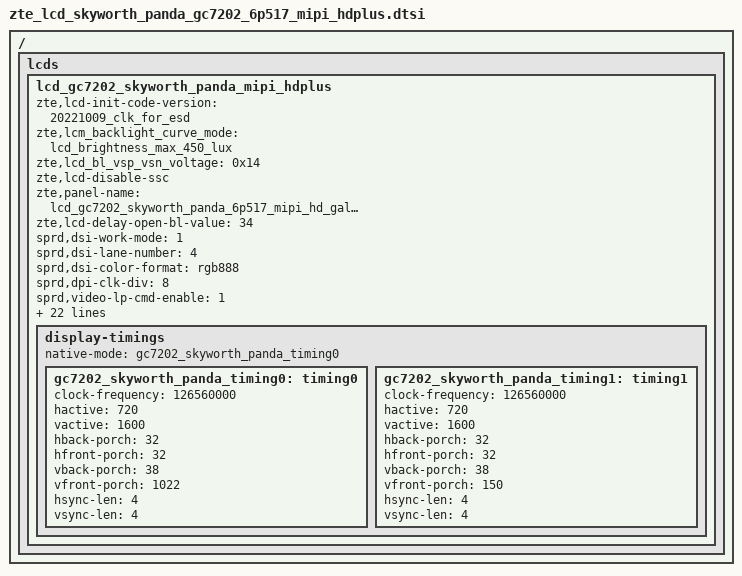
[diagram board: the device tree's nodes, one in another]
/ {
	fragment {
		target-path = "/";
		__overlay__ {
			lcds {
				lcd_gc7202_skyworth_panda_mipi_hdplus: lcd_gc7202_skyworth_panda_mipi_hdplus {
					zte,lcd-init-code-version = "20221009_clk_for_esd";

					zte,lcm_backlight_curve_mode = "lcd_brightness_max_450_lux";
					zte,lcd_bl_vsp_vsn_voltage = <0x14>;
					zte,lcd-disable-ssc;
					zte,panel-name = "lcd_gc7202_skyworth_panda_6p517_mipi_hd_galaxycore_4lane";
					zte,lcd-delay-open-bl-value = <34>;

					sprd,dsi-work-mode = <1>;
					sprd,dsi-lane-number = <4>;
					sprd,dsi-color-format = "rgb888";

					sprd,dpi-clk-div = <8>;
					sprd,video-lp-cmd-enable = <1>;
					sprd,hporch-lp-disable = <1>;

					sprd,phy-bit-clock = <1012480>;
					sprd,phy-escape-clock = <20000>;/* kHz */

					sprd,width-mm = <67932>;
					sprd,height-mm = <150960>;

					sprd,esd-check-enable = <1>;/* 0:close , 1:open */
					sprd,esd-check-mode = <0>;/* 0:REG ,1:TE  */
					sprd,esd-check-period = <2000>;
					sprd,esd-check-register = <0x0A>;
					sprd,esd-check-value = <0x9C>;

		sprd,reset-on-sequence = <1 10>, <0 10>, <1 35>, <0 10>, <1 10>, <0 10>, <1 10>, <0 10>, <1 30>;
		sprd,reset-off-sequence = <1 10>;
		sprd,use-dcs-write;
		sprd,initial-command = [
39 00 00 04 FF 55 AA 66
15 00 00 02 FF 20
15 00 00 02 FB 00
15 00 00 02 FF 21
15 00 00 02 FB 00
15 00 00 02 FF 22
15 00 00 02 FB 00
15 00 00 02 FF 23
15 00 00 02 FB 00
15 00 00 02 FF 24
15 00 00 02 FB 00
15 00 00 02 FF 26
15 00 00 02 FB 00
15 00 00 02 FF 27
15 00 00 02 FB 00
15 00 00 02 FF A3
15 00 00 02 FB 00
15 00 00 02 FF B3
15 00 00 02 FB 00
15 00 00 02 FF C3
15 00 00 02 FB 00
15 00 00 02 FF 22
15 00 00 02 E4 00
15 00 00 02 01 06
15 00 00 02 02 40
15 00 00 02 25 08
15 00 00 02 26 00
15 00 00 02 2E AA
15 00 00 02 2F 00
15 00 00 02 36 09
15 00 00 02 37 00
15 00 00 02 3F AA
15 00 00 02 40 00
15 00 00 02 0E 33
15 00 00 02 DC 00
15 00 00 02 E0 01
15 00 00 02 08 40
15 00 00 02 FF 21
15 00 00 02 01 25
15 00 00 02 02 05
15 00 00 02 03 06
15 00 00 02 04 25
15 00 00 02 05 25
15 00 00 02 06 01
15 00 00 02 07 0F
15 00 00 02 08 0D
15 00 00 02 09 0B
15 00 00 02 0A 09
15 00 00 02 0B 23
15 00 00 02 0C 23
15 00 00 02 0D 25
15 00 00 02 0E 25
15 00 00 02 0F 25
15 00 00 02 10 25
15 00 00 02 11 25
15 00 00 02 12 25
15 00 00 02 13 25
15 00 00 02 14 25
15 00 00 02 15 25
15 00 00 02 16 25
15 00 00 02 17 25
15 00 00 02 18 04
15 00 00 02 19 06
15 00 00 02 1A 25
15 00 00 02 1B 25
15 00 00 02 1C 00
15 00 00 02 1D 0E
15 00 00 02 1E 0C
15 00 00 02 1F 0A
15 00 00 02 20 08
15 00 00 02 21 23
15 00 00 02 22 23
15 00 00 02 23 25
15 00 00 02 24 25
15 00 00 02 25 25
15 00 00 02 26 25
15 00 00 02 27 25
15 00 00 02 28 25
15 00 00 02 29 25
15 00 00 02 2A 25
15 00 00 02 2B 25
15 00 00 02 2D 25
15 00 00 02 45 73
15 00 00 02 7E 03
15 00 00 02 C2 85
15 00 00 02 7F 22
15 00 00 02 8B 22
15 00 00 02 80 02
15 00 00 02 8C 19
15 00 00 02 81 19
15 00 00 02 8D 02
15 00 00 02 AF 40
15 00 00 02 B0 40
15 00 00 02 83 03
15 00 00 02 8F 03
15 00 00 02 84 55
15 00 00 02 90 55
15 00 00 02 85 42
15 00 00 02 91 42
15 00 00 02 87 00
15 00 00 02 93 00
15 00 00 02 2E 00
15 00 00 02 88 A7
15 00 00 02 89 20
15 00 00 02 8A 33
15 00 00 02 94 A7
15 00 00 02 95 20
15 00 00 02 96 33
15 00 00 02 46 54
15 00 00 02 4C 54
15 00 00 02 5E 42
15 00 00 02 64 42
15 00 00 02 82 50
15 00 00 02 8E 50
15 00 00 02 47 02
15 00 00 02 4D 01
15 00 00 02 48 01
15 00 00 02 4E 02
15 00 00 02 5F 06
15 00 00 02 65 07
15 00 00 02 60 07
15 00 00 02 66 06
15 00 00 02 76 40
15 00 00 02 77 40
15 00 00 02 7A 44
15 00 00 02 7B 44
15 00 00 02 6A 42
15 00 00 02 7C 54
15 00 00 02 6B 06
15 00 00 02 6C 07
15 00 00 02 6D 55
15 00 00 02 6E 55
15 00 00 02 49 55
15 00 00 02 4A 55
15 00 00 02 4F 55
15 00 00 02 50 55
15 00 00 02 61 55
15 00 00 02 62 55
15 00 00 02 67 55
15 00 00 02 68 55
15 00 00 02 C6 56
15 00 00 02 D1 13
15 00 00 02 FF B3
15 00 00 02 4A 00
15 00 00 02 7D 28
15 00 00 02 5B 00
15 00 00 02 48 23
15 00 00 02 7C 88
15 00 00 02 3E 03
15 00 00 02 3F 3f
15 00 00 02 5E 10
15 00 00 02 58 84
15 00 00 02 51 51
15 00 00 02 FF 20
15 00 00 02 29 01
15 00 00 02 2D 1F
15 00 00 02 02 21
15 00 00 02 03 21
15 00 00 02 04 46
15 00 00 02 05 46
15 00 00 02 0A 19
15 00 00 02 0B 19
15 00 00 02 0C 43
15 00 00 02 0D 43
15 00 00 02 77 74
15 00 00 02 78 74
15 00 00 02 A5 00
15 00 00 02 A6 FF
15 00 00 02 A9 00
15 00 00 02 AA FF
15 00 00 02 AD 00
15 00 00 02 AE FF
15 00 00 02 B1 00
15 00 00 02 B2 FF
15 00 00 02 C3 00
15 00 00 02 C4 65
15 00 00 02 C5 00
15 00 00 02 C6 65
15 00 00 02 B3 00
15 00 00 02 B4 28
15 00 00 02 B5 01
15 00 00 02 B6 04
15 00 00 02 7E 01
15 00 00 02 7F 00
15 00 00 02 80 01
15 00 00 02 81 00
15 00 00 02 82 00
15 00 00 02 83 04
15 00 00 02 84 04
15 00 00 02 85 01
15 00 00 02 86 A6
15 00 00 02 87 01
15 00 00 02 88 8B
15 00 00 02 8A 03
15 00 00 02 8B 03
15 00 00 02 18 44
15 00 00 02 17 51
15 00 00 02 12 A2
15 00 00 02 15 4C
15 00 00 02 A3 44
15 00 00 02 A7 44
15 00 00 02 D3 06
15 00 00 02 24 99
15 00 00 02 25 16
15 00 00 02 FF 23
39 00 00 11 01 00 00 00 2E 00 5D 00 7D 00 95 00 AA 00 C0 00 CF
39 00 00 11 02 00 DF 01 0D 01 30 01 61 01 82 01 B4 01 DE 01 DF
39 00 00 11 03 02 0B 02 43 02 6B 02 A0 02 C4 02 F6 03 06 03 18
39 00 00 0D 04 03 2C 03 44 03 5E 03 85 03 C2 03 FF
39 00 00 11 05 00 00 00 2E 00 5D 00 7D 00 95 00 AA 00 C0 00 CF
39 00 00 11 06 00 DF 01 0D 01 30 01 61 01 82 01 B4 01 DE 01 DF
39 00 00 11 07 02 0B 02 43 02 6B 02 A0 02 C4 02 F6 03 06 03 18
39 00 00 0D 08 03 2C 03 44 03 5e 03 85 03 C2 03 FF
39 00 00 11 09 00 00 00 2E 00 5D 00 7D 00 95 00 AA 00 C0 00 CF
39 00 00 11 0A 00 DF 01 0D 01 30 01 61 01 82 01 B4 01 DE 01 DF
39 00 00 11 0B 02 0B 02 43 02 6B 02 A0 02 C4 02 F6 03 06 03 18
39 00 00 0D 0C 03 2C 03 44 03 5e 03 85 03 C2 03 FF
39 00 00 11 0D 00 00 00 2E 00 5D 00 7D 00 95 00 AA 00 C0 00 CF
39 00 00 11 0E 00 DF 01 0D 01 30 01 61 01 82 01 B4 01 DE 01 DF
39 00 00 11 0F 02 0B 02 43 02 6B 02 A0 02 C4 02 F6 03 06 03 18
39 00 00 0D 10 03 2C 03 44 03 5e 03 85 03 C2 03 FF
39 00 00 11 11 00 00 00 2E 00 5D 00 7D 00 95 00 AA 00 C0 00 CF
39 00 00 11 12 00 DF 01 0D 01 30 01 61 01 82 01 B4 01 DE 01 DF
39 00 00 11 13 02 0B 02 43 02 6B 02 A0 02 C4 02 F6 03 06 03 18
39 00 00 0D 14 03 2C 03 44 03 5e 03 85 03 C2 03 FF
39 00 00 11 15 00 00 00 2E 00 5D 00 7D 00 95 00 AA 00 C0 00 CF
39 00 00 11 16 00 DF 01 0D 01 30 01 61 01 82 01 B4 01 DE 01 DF
39 00 00 11 17 02 0B 02 43 02 6B 02 A0 02 C4 02 F6 03 06 03 18
39 00 00 0D 18 03 2C 03 44 03 5e 03 85 03 C2 03 FF
15 00 00 02 FF b3
15 00 00 02 61 be
15 00 00 02 FF A3
15 00 00 02 FA 01
15 00 00 02 35 01
15 00 00 02 05 05
15 00 00 02 FF 26
39 00 00 05 1D 0C 00 00 00
15 00 00 02 FF A3
15 00 00 02 FB 00
15 00 00 02 4D FF
15 00 00 02 4E 0F
15 00 00 02 4F FF
15 00 00 02 50 FF
15 00 00 02 51 FF
15 00 00 02 52 FF
15 00 00 02 53 FF
15 00 00 02 54 FF
15 00 00 02 FF C3
15 00 00 02 FB 00
15 00 00 02 13 07
15 00 00 02 FF 10
15 00 00 02 36 08
15 00 00 02 69 00
15 00 00 02 35 00
15 00 00 02 FF 24
15 00 00 02 7D 55
39 00 00 04 FF 66 99 55
39 00 00 02 FF 10
23 87 00 02 11 00 
23 14 00 02 29 00 
		];

		sprd,sleep-in-command = [
39 00 00 04 FF 55 AA 66
15 00 00 02 FF 20
15 00 00 02 4A 01
15 00 00 02 48 10
15 00 00 02 49 00
15 00 00 02 FF 21
15 00 00 02 D1 00
15 00 00 02 FF 27
39 00 00 04 D1 0F 44 03
15 00 00 02 FF A3
15 00 00 02 0F 01
15 00 00 02 0E 03
15 00 00 02 FF 10
15 32 00 02 28 00
15 00 00 02 FF B3
15 32 00 02 61 BE
15 00 00 02 FF 10
15 78 00 02 10 00
15 00 00 02 FF B3
15 00 00 02 61 00
15 00 00 02 FF A3
15 00 00 02 0F 00
15 00 00 02 0E 00
39 00 00 04 FF 55 AA 66
15 00 00 02 FF 26
39 00 00 03 1D 2A 80
15 00 00 02 FF B3
15 00 00 02 04 16
15 00 00 02 01 99
15 00 00 02 10 09
15 00 00 02 FF C3
15 14 00 02 12 01
			];
		sprd,sleep-out-command = [
			13 78 00 01 11
			13 64 00 01 29
			];
		zte,brightness-levels = [
			39 00 00 03 51 06 66
			];

					display-timings {
						native-mode = <&gc7202_skyworth_panda_timing0>;
						gc7202_skyworth_panda_timing0: timing0 {/*60hz*/
							clock-frequency = <126560000>;
							hactive = <720>;
 							vactive = <1600>;
 							hback-porch = <32>;
 							hfront-porch = <32>;
							vback-porch = <38>;
							vfront-porch = <1022>;
 							hsync-len = <4>;
 							vsync-len = <4>;
 
 						};
						 gc7202_skyworth_panda_timing1: timing1 {/*90hz*/
							clock-frequency = <126560000>;
 							hactive = <720>;
 							vactive = <1600>;
 							hback-porch = <32>;
 							hfront-porch = <32>;
							vback-porch = <38>;
							vfront-porch = <150>;
 							hsync-len = <4>;
 							vsync-len = <4>;
 
						};
					};
					/*
					oled-backlight {
						default-brightness-level = <1632>;
						sprd,max-level = <4095>;
						brightness-levels = [
							39 00 00 03 51 00 00
							39 00 00 02 53 2C
						];
					};*/
				};
			};
		};
	};
};
